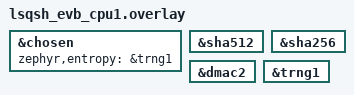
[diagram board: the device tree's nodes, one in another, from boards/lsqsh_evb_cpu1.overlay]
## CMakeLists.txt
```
# Copyright (c) 2022 Intel Corporation.
# SPDX-License-Identifier: Apache-2.0

cmake_minimum_required(VERSION 3.20.0)
find_package(Zephyr REQUIRED HINTS $ENV{ZEPHYR_BASE})
project(throughput)

target_sources(app PRIVATE src/main.c)
```

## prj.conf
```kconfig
# Zephyr crypto disabled, only mbedtls tests
CONFIG_CRYPTO=n
CONFIG_CRYPTO_LINKEDSEMI_SHA256=n
CONFIG_CRYPTO_LINKEDSEMI_SHA512=n

CONFIG_LOG=y
CONFIG_LOG_MODE_MINIMAL=y
CONFIG_TIMING_FUNCTIONS=y
# CONFIG_MINIMAL_LIBC=y
CONFIG_PICOLIBC=y
CONFIG_ENTROPY_GENERATOR=y

# mbedtls support
CONFIG_MBEDTLS=y
CONFIG_MBEDTLS_BUILTIN=y
CONFIG_CUSTOM_MBEDTLS_CFG_FILE=y
CONFIG_MBEDTLS_CFG_FILE="config-linkedsemi-tls.h"

CONFIG_MBEDTLS_SHA224=y
CONFIG_MBEDTLS_SHA256=y

CONFIG_MBEDTLS_SHA384=y
CONFIG_MBEDTLS_SHA512=y

CONFIG_MBEDTLS_THREADING_LINKEDSEMI_ALT=y

# OTBN RSA support
CONFIG_SHA256_CLOCK_RESET=y
CONFIG_SHA512_CLOCK_RESET=y

CONFIG_DMA=y

# OTBN ECDSA support
CONFIG_MBEDTLS_ECP_C=y
CONFIG_MBEDTLS_ECDSA_C=y

CONFIG_MBEDTLS_ENABLE_HEAP=y
CONFIG_MBEDTLS_HEAP_SIZE=65536

CONFIG_MAIN_STACK_SIZE=32768
CONFIG_LS_OTBN_OPERATION_TIMEOUT_MS=60000

# linkedsemi cncryption acceleration
# ----------hardware----------
# sha224/sha256
CONFIG_MBEDTLS_SHA224_SHA256_LINKEDSEMI_HARDWARE_ALT=n
# sm3
CONFIG_MBEDTLS_SM3_LINKEDSEMI_HARDWARE_ALT=n
# hash
CONFIG_MBEDTLS_SHA384_SHA512_LINKEDSEMI_HARDWARE_ALT=n
# AES/SM4 support
CONFIG_MBEDTLS_CIPHER_AES_LINKEDSEMI=y
CONFIG_MBEDTLS_SM4_LINKEDSEMI_HARDWARE_ALT=y

# ----------otbn----------
CONFIG_MBEDTLS_SHA224_SHA256_LINKEDSEMI_OTBN_ALT=y
CONFIG_MBEDTLS_SM3_LINKEDSEMI_OTBN_ALT=y
# ecdsa-p256r1 p384r1 sm2
CONFIG_MBEDTLS_ECDSA_SECP256R1_SECP384R1_SM2_LINKEDSEMI_OTBN_ALT=y
# HASH
CONFIG_MBEDTLS_SHA384_SHA512_LINKEDSEMI_OTBN_ALT=y
# RSA
CONFIG_MBEDTLS_RSA_LINKEDSEMI_OTBN_ALT=y
```

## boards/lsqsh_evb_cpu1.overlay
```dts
&chosen {
    zephyr,entropy = &trng1;
};

&sha512 {
    status = "okay";
};

&sha256 {
    status = "okay";
};

&dmac2 {
    status = "okay";
};

&trng1 {
    status = "okay";
};
```

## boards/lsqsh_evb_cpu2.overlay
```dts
&sha512 {
    status = "okay";
};

&sha256 {
    status = "okay";
};

&dmac2 {
    status = "okay";
};
```

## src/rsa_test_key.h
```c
/*
 *  Hard-coded 2048-bit RSA test key for mbedtls_test.
 *
 *  Generated with OpenSSL for OTBN RSA validation only.
 */

#ifndef RSA_TEST_KEY_H_
#define RSA_TEST_KEY_H_

#ifdef __cplusplus
extern "C" {
#endif

static const unsigned char rsa2048_n[256] = {
    0xc2, 0x88, 0x79, 0x76, 0x96, 0x6e, 0x85, 0x76, 0xc7, 0x34, 0x85, 0xd1, 0xe3, 0x3e, 0xf9, 0xd1,
    0x58, 0x0c, 0xc2, 0x78, 0x77, 0xc2, 0x1a, 0xb3, 0xa7, 0xdd, 0xcf, 0xb9, 0xb3, 0xfc, 0xef, 0x06,
    0x12, 0x04, 0x58, 0xe8, 0xb7, 0xe7, 0x85, 0x40, 0xa3, 0x7e, 0xf6, 0x46, 0xb2, 0x2a, 0x48, 0xb1,
    0x78, 0xfb, 0xdf, 0xa3, 0xf5, 0x02, 0x35, 0xdd, 0x37, 0x14, 0xbb, 0x75, 0x47, 0x7f, 0x74, 0x2b,
    0x2b, 0x86, 0x45, 0x51, 0x70, 0x99, 0x24, 0x8c, 0xac, 0x20, 0x73, 0x20, 0x9c, 0x92, 0x99, 0xa7,
    0x2c, 0x36, 0xf2, 0xb7, 0x5d, 0x2d, 0x81, 0x8f, 0x07, 0xfa, 0x03, 0x64, 0x35, 0x60, 0x71, 0xbd,
    0xb6, 0xa7, 0x82, 0xc5, 0xfb, 0x1e, 0x94, 0xfe, 0xf9, 0x0b, 0x98, 0xea, 0x22, 0x98, 0xf3, 0xfc,
    0xc0, 0x1a, 0xad, 0x37, 0x7c, 0x2b, 0xeb, 0xf6, 0x90, 0xba, 0x87, 0xc5, 0x6f, 0xf8, 0xec, 0x7a,
    0xb2, 0x70, 0xfd, 0xad, 0xc5, 0x97, 0x9d, 0xd8, 0xb5, 0xb4, 0x25, 0x2e, 0xd7, 0xa3, 0x1b, 0x3f,
    0xc9, 0x9b, 0xe0, 0x40, 0xce, 0xb4, 0x8d, 0x0b, 0x97, 0xe7, 0xea, 0xe9, 0xfb, 0x5d, 0x52, 0xe4,
    0x1f, 0xc1, 0x6c, 0x55, 0xfb, 0x32, 0x30, 0x7c, 0xb7, 0x48, 0x06, 0x83, 0xf7, 0xc6, 0x3c, 0xcb,
    0x3d, 0xc3, 0x0d, 0x96, 0x4f, 0x07, 0x34, 0xa7, 0x95, 0xbe, 0xe5, 0x3e, 0x24, 0xfb, 0x78, 0x87,
    0x74, 0x13, 0xee, 0xef, 0xc6, 0x3c, 0xc0, 0x75, 0x34, 0x43, 0x69, 0xbb, 0x51, 0xb2, 0x77, 0x67,
    0xab, 0x14, 0x84, 0xe0, 0x05, 0x6b, 0xe7, 0x40, 0xad, 0x3a, 0xf2, 0x9a, 0x31, 0x3c, 0x1f, 0x1f,
    0x97, 0x2c, 0xb5, 0xba, 0x95, 0x11, 0x29, 0xa1, 0xf4, 0xb2, 0x2b, 0xa3, 0x17, 0x45, 0x67, 0xa9,
    0xe0, 0x9d, 0xca, 0x53, 0xc6, 0x50, 0x84, 0x7f, 0x1e, 0x8f, 0x27, 0xcb, 0xe8, 0x58, 0xe9, 0xef,
};

static const unsigned char rsa2048_d[256] = {
    0x15, 0xae, 0x30, 0x1b, 0x4f, 0x58, 0xb1, 0xf7, 0x32, 0xec, 0x5f, 0x9d, 0xac, 0xbd, 0xf0, 0x09,
    0xac, 0xce, 0x7f, 0x3d, 0xfd, 0xda, 0xdc, 0x2e, 0xf9, 0x9e, 0x76, 0xf0, 0x33, 0x67, 0x15, 0x1c,
    0x90, 0x15, 0x7b, 0xf3, 0x33, 0xcb, 0xd1, 0xc6, 0x0a, 0x72, 0xb3, 0xef, 0xdd, 0x1b, 0x69, 0x4e,
    0x9e, 0x35, 0x34, 0x0f, 0x89, 0xd6, 0xdd, 0x39, 0xf2, 0x51, 0x95, 0x32, 0xd4, 0xed, 0x17, 0x7d,
    0x58, 0x34, 0x76, 0xb5, 0x44, 0xdf, 0x4c, 0x7b, 0x81, 0x13, 0x7c, 0xc1, 0x3d, 0xb1, 0xf8, 0xfd,
    0xf0, 0xa7, 0x8f, 0x15, 0x70, 0x85, 0x09, 0xd3, 0x6f, 0x08, 0x26, 0x28, 0x9c, 0xea, 0x4a, 0xc2,
    0xe2, 0x00, 0x79, 0x4a, 0xa7, 0x5a, 0x19, 0x30, 0xf1, 0x80, 0xa1, 0x62, 0x36, 0xc8, 0xe5, 0x28,
    0x5e, 0x20, 0x9a, 0xfd, 0x7c, 0x11, 0x49, 0x13, 0x09, 0xbe, 0x40, 0x33, 0x78, 0xef, 0x3d, 0x2b,
    0x9d, 0xa5, 0x7e, 0xb8, 0x02, 0xa4, 0xdc, 0x80, 0x83, 0x3a, 0xa9, 0x7b, 0x24, 0x0f, 0x9b, 0x9a,
    0x61, 0x62, 0x4a, 0x60, 0xbf, 0xa4, 0xec, 0x4c, 0x85, 0xd4, 0x57, 0x18, 0x4e, 0x30, 0x48, 0xfa,
    0x3e, 0x8d, 0x6e, 0x2e, 0xf8, 0xe1, 0xc9, 0xd6, 0xa9, 0xf4, 0x49, 0x42, 0xd4, 0xdd, 0x68, 0xeb,
    0xd9, 0x48, 0xea, 0x6a, 0xd9, 0xce, 0xf4, 0x23, 0x07, 0x0b, 0xd4, 0x9e, 0x89, 0x91, 0x88, 0x1b,
    0xd5, 0xc9, 0xa2, 0x13, 0xff, 0x39, 0xb6, 0x89, 0x9c, 0x92, 0x79, 0x01, 0x2d, 0x53, 0x58, 0x05,
    0xc3, 0x30, 0x28, 0x8e, 0xc6, 0xd6, 0x31, 0x4b, 0x35, 0xf5, 0xd0, 0x50, 0xab, 0xf1, 0x1f, 0xaf,
    0xeb, 0x02, 0x4a, 0xf6, 0x53, 0x7f, 0x17, 0x09, 0xfb, 0x32, 0x7a, 0x4a, 0x8f, 0x73, 0x58, 0xbc,
    0x70, 0x28, 0x66, 0xce, 0x60, 0xa3, 0xb0, 0x49, 0x17, 0x5e, 0x11, 0xc3, 0x11, 0xfc, 0x0d, 0x41,
};

static const unsigned char rsa2048_e[3] = {
    0x01, 0x00, 0x01
};

static const unsigned char rsa2048_ciphertext[256] = {
    0x38, 0x9a, 0x9f, 0xc8, 0xb5, 0x37, 0x8e, 0x33, 0x2a, 0xdd, 0xe4, 0x68, 0x6f, 0xb4, 0xed, 0x73,
    0x60, 0x82, 0xc4, 0x6d, 0x90, 0x87, 0x03, 0x1c, 0xb3, 0x4f, 0xb2, 0x36, 0xe5, 0x4c, 0x7e, 0xd6,
    0xe5, 0xa9, 0xfd, 0x2e, 0x68, 0x76, 0x15, 0x82, 0xdf, 0x82, 0x16, 0xc4, 0x27, 0x60, 0xc9, 0xa6,
    0x0f, 0x50, 0x75, 0x5f, 0xee, 0xfd, 0xbb, 0xd1, 0x26, 0x83, 0xf1, 0x66, 0x69, 0xe9, 0x4d, 0x69,
    0xa2, 0xd0, 0x82, 0x85, 0xcc, 0x3a, 0x25, 0xff, 0x2f, 0x0c, 0x71, 0x6d, 0x42, 0x88, 0x7b, 0xa2,
    0xf6, 0x7e, 0x52, 0x96, 0x86, 0xd8, 0xc9, 0x2f, 0x51, 0x92, 0xf0, 0x32, 0x86, 0x7c, 0xcb, 0x23,
    0x56, 0xaf, 0x63, 0x20, 0x35, 0x6c, 0x43, 0xb7, 0x35, 0x7e, 0x55, 0x8c, 0x59, 0xad, 0x69, 0xef,
    0xe6, 0x9d, 0x47, 0x5a, 0x78, 0xee, 0xc0, 0x38, 0xf2, 0x01, 0x17, 0xca, 0xa4, 0x61, 0xec, 0x27,
    0x3f, 0x28, 0x4f, 0x18, 0xf9, 0x0f, 0xe0, 0x65, 0x44, 0xe1, 0xde, 0xb5, 0x65, 0x1e, 0x27, 0x72,
    0x10, 0x49, 0xe9, 0x5a, 0x69, 0x76, 0x38, 0xda, 0x49, 0xc9, 0x4a, 0xfa, 0x85, 0xa6, 0xe0, 0x5d,
    0x4e, 0xd0, 0x90, 0x92, 0x34, 0x93, 0xaf, 0x75, 0xe4, 0x33, 0x8c, 0xfa, 0x8c, 0x27, 0xf0, 0xfc,
    0x6d, 0x0c, 0x4e, 0xa3, 0xf7, 0x7a, 0xf3, 0xf4, 0x6e, 0xcd, 0x79, 0xf9, 0x85, 0x72, 0x33, 0x43,
    0xad, 0x21, 0x98, 0x1e, 0xa8, 0x7f, 0x0d, 0xb4, 0xcd, 0xea, 0xd6, 0x8a, 0x4c, 0xf8, 0xcd, 0x66,
    0xda, 0x6d, 0xab, 0xba, 0x7a, 0xbd, 0x31, 0xe1, 0xe0, 0x46, 0xf7, 0x94, 0xd6, 0x82, 0xdd, 0x04,
    0x7d, 0xf3, 0xac, 0x2b, 0x12, 0x30, 0x15, 0x99, 0xbb, 0x72, 0xea, 0x52, 0xb9, 0xce, 0x7f, 0x89,
    0x2f, 0x1d, 0x0d, 0x10, 0x0e, 0xf9, 0x59, 0x7b, 0xc5, 0x68, 0x0d, 0xa6, 0x9d, 0x1e, 0xf4, 0x8d,
};

static const unsigned char rsa2048_signature[256] = {
    0x22, 0x1f, 0xe7, 0x4e, 0x83, 0x17, 0xd6, 0x3b, 0x65, 0x3a, 0xb8, 0xef, 0x41, 0x48, 0x8c, 0x4e,
    0x39, 0x18, 0x30, 0x59, 0xcc, 0xe8, 0xa7, 0x5c, 0xb9, 0x6e, 0xc8, 0x77, 0x59, 0xbc, 0x15, 0xc2,
    0x93, 0x97, 0xf2, 0x3f, 0x3c, 0xcc, 0x4f, 0x16, 0x18, 0xdf, 0x33, 0xad, 0x94, 0x15, 0xd9, 0xf0,
    0x29, 0x17, 0xf1, 0x62, 0x8b, 0x50, 0x52, 0xd9, 0x84, 0x7a, 0x86, 0xee, 0x64, 0x29, 0x68, 0x70,
    0xd3, 0x45, 0xcc, 0x09, 0x99, 0x17, 0x37, 0x5a, 0xe2, 0xfb, 0x4f, 0xb0, 0x00, 0x41, 0x79, 0x1e,
    0x33, 0x6a, 0x89, 0x70, 0xa8, 0x57, 0xb4, 0x6c, 0x36, 0x7d, 0x9f, 0x49, 0x7b, 0xeb, 0xfc, 0xb1,
    0x32, 0x08, 0x54, 0xe9, 0x1e, 0xfa, 0xf1, 0xdd, 0x5c, 0x84, 0x27, 0x2c, 0xfb, 0xbf, 0xba, 0x3a,
    0x86, 0x0f, 0xca, 0x71, 0x7e, 0x23, 0x66, 0x24, 0xaa, 0x5d, 0x8b, 0x22, 0xbc, 0x7a, 0x31, 0xd2,
    0x85, 0x79, 0x23, 0x56, 0x8a, 0x05, 0xc9, 0x12, 0x94, 0xe1, 0xd3, 0xcf, 0x0f, 0x0a, 0xf0, 0x63,
    0x30, 0x0c, 0x7f, 0xb1, 0xdf, 0x9e, 0x3b, 0x84, 0x64, 0x8d, 0x5e, 0x90, 0x1b, 0xe7, 0xe0, 0x01,
    0x63, 0xdc, 0x24, 0x83, 0x5e, 0x05, 0x81, 0x5b, 0xeb, 0x6b, 0x51, 0x29, 0x06, 0xeb, 0x9e, 0x88,
    0x46, 0x94, 0xf3, 0x1e, 0xb6, 0x6e, 0x5b, 0xb0, 0x02, 0xbb, 0x5e, 0x52, 0x8a, 0xc8, 0x85, 0xb7,
    0x69, 0xf4, 0x28, 0xa3, 0x68, 0xaa, 0x95, 0x05, 0x0f, 0xc7, 0xfd, 0x59, 0x40, 0xde, 0xcc, 0xe1,
    0xa9, 0x3a, 0x9a, 0x35, 0xca, 0x83, 0x7c, 0x11, 0x54, 0xe8, 0xf8, 0xba, 0xaa, 0x48, 0x73, 0x38,
    0x95, 0x4b, 0x1f, 0x09, 0x27, 0x3e, 0xf0, 0x0c, 0x99, 0xed, 0xb9, 0xef, 0x76, 0x0f, 0x6b, 0x49,
    0xc1, 0x8d, 0x73, 0xd0, 0x4a, 0x40, 0xd4, 0xf2, 0x64, 0x55, 0x8e, 0xf2, 0x06, 0x81, 0x69, 0x69,
};

#ifdef __cplusplus
}
#endif

#endif /* RSA_TEST_KEY_H_ */
```
